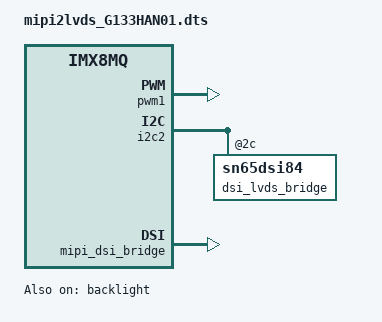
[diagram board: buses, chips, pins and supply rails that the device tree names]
/dts-v1/;
/plugin/;
/ {
	compatible = "fsl,imx8mq";

	fragment@0 {
		target = <&pwm1>;
		__overlay__ {
			status = "okay";
		};
	};
	fragment@1 {
		target = <&backlight>;
		__overlay__ {
			status = "okay";
			pwms = <&pwm1 0 2000000 0>;
                        disable_delay = <15>;
                        power-sequence-reverse;
                        minimal-brightness-level = <15>;
		};
	};
	fragment@2 {
		target = <&i2c2>;
		__overlay__ {
			status = "okay";
			dsi_lvds_bridge: sn65dsi84@2c {
				status = "okay";
				lvds-clk-rate = <70000000>;
				lvds-format = <1>;
				lvds-bpp = <24>;
				lvds-width-mm = <293>;
				lvds-height-mm = <165>;
				sync_delay = <33>;
				dual-link;
				init-pass-pattern=<0x3D>;

				t1=<0>;
				t2=<250>;
				t3=<100>;
				t4=<100>;
				t5=<20>;
				t6=<0>;
				t7=<1000>;

				bpc=<8>;
				bus-format = <0x100a>;
				dsi,flags = <0x5>;
				dsi,format = <0>;
				dsi-lanes = <4>;

				display-timings {
					lvds {
						clock-frequency = <140000000>;
						hactive = <1920>;
						vactive = <1080>;
						hfront-porch = <20>;//62
						hback-porch = <96>;
						hsync-len = <64>;
						vfront-porch = <8>;
						vsync-len = <20>;
						vback-porch = <8>;
						hsync-active = <0>;
						vsync-active = <0>;
						de-active = <0>;
						pixelclk-active = <0>;
					};
				};
			};
		};
	};
	fragment@3 {
		target = <&mipi_dsi_bridge>;
		__overlay__ {
			status = "okay";
			//best-match;
			clock-drop-level = <2>;
			panel@0 {
				status = "disabled";
			};
		};
	};
	fragment@4 {
		target = <&mipi_dsi>;
		__overlay__ {
			sync-pol = <1>;
			pwr-delay = <100>;
			//best-match;
		};
	};
	fragment@5 {
		target = <&lcdif>;
		__overlay__ {
			max-res = <4096>, <4096>;
		};
	};

};
